AUTOSAR XML (schema 00048)
package /ComponentTypes
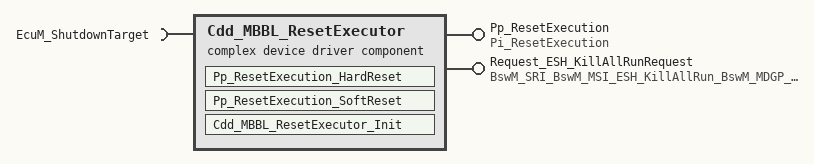
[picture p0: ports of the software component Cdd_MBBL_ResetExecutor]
  complex device driver sw component type Cdd_MBBL_ResetExecutor
    provide port Pp_ResetExecution: provided-com-specs=[{operation=HardReset, queue-length=1}, {operation=SoftReset, queue-length=1}], provided-interface=Pi_ResetExecution
    provide port Request_ESH_KillAllRunRequest: nonqueued-sender-com-spec=requestedMode, provided-interface=BswM_SRI_BswM_MSI_ESH_KillAllRun_BswM_MDGP_ESH_KillAllRun
    require port EcuM_ShutdownTarget: required-com-specs=[SelectShutdownTarget, GetShutdownTarget, GetLastShutdownTarget, SelectShutdownCause, GetShutdownCause], required-interface=EcuM_ShutdownTarget
    behavior Cdd_MBBL_ResetExecutor_InternalBehavior
      exclusive area EA_IllegalMcuResetReturn
      operation invoked event OIT_Pp_ResetExecution_HardReset_Pp_ResetExecution_HardReset: start-on-event=Pp_ResetExecution_HardReset, operation=Pp_ResetExecution.HardReset
      operation invoked event OIT_Pp_ResetExecution_SoftReset_Pp_ResetExecution_SoftReset: start-on-event=Pp_ResetExecution_SoftReset, operation=Pp_ResetExecution.SoftReset
      init event Cdd_MBBL_ResetExecutor_InitEvent: start-on-event=Cdd_MBBL_ResetExecutor_Init
      runnable Pp_ResetExecution_HardReset: can-enter-exclusive-area=EA_IllegalMcuResetReturn  # ------------------------------------------------------------------------------------- This runnable executes all required steps for a hard reset: - Preparation of Watchdog(s) for reset --> optional step (depends on value of prepareWatchdog) - Call of Mcu_PerformReset If the Mcu-call fails it will try the second reset path by waiting for a watchdog reset in an infinite loop with locked interrupts. This runnable should never return. -------------------------------------------------------------------------------------
      runnable Pp_ResetExecution_SoftReset  # ------------------------------------------------------------------------------------- This server runnable executes all required steps for a soft reset: - Set the ECUM shutdown target to MCU reset --> This ensures that after a successful shutdown the EcuM performs a reset instead of a shutdown - Kill all BswM run requests --> This triggers the BswM to perform a regular shutdown ignoring all other reasons as to why the ECU might still be awake If any of those requests fails the runnable will return a negative response code. -------------------------------------------------------------------------------------
        data-send-points:
          access SEND_Request_ESH_KillAllRunRequest_requestedMode: accessed-variable=Request_ESH_KillAllRunRequest.requestedMode
        sync call SC_EcuM_ShutdownTarget_SelectShutdownTarget: operation=EcuM_ShutdownTarget.SelectShutdownTarget
      runnable Cdd_MBBL_ResetExecutor_Init  # ------------------------------------------------------------------------------------- This runnable is currently not used. -------------------------------------------------------------------------------------
  swc implementation Cdd_MBBL_ResetExecutor_Implementation: behavior=Cdd_MBBL_ResetExecutor_InternalBehavior
    code-descriptors:
      code Default: artifact-descriptors=autosar-engineering-object=category=SWSRC
